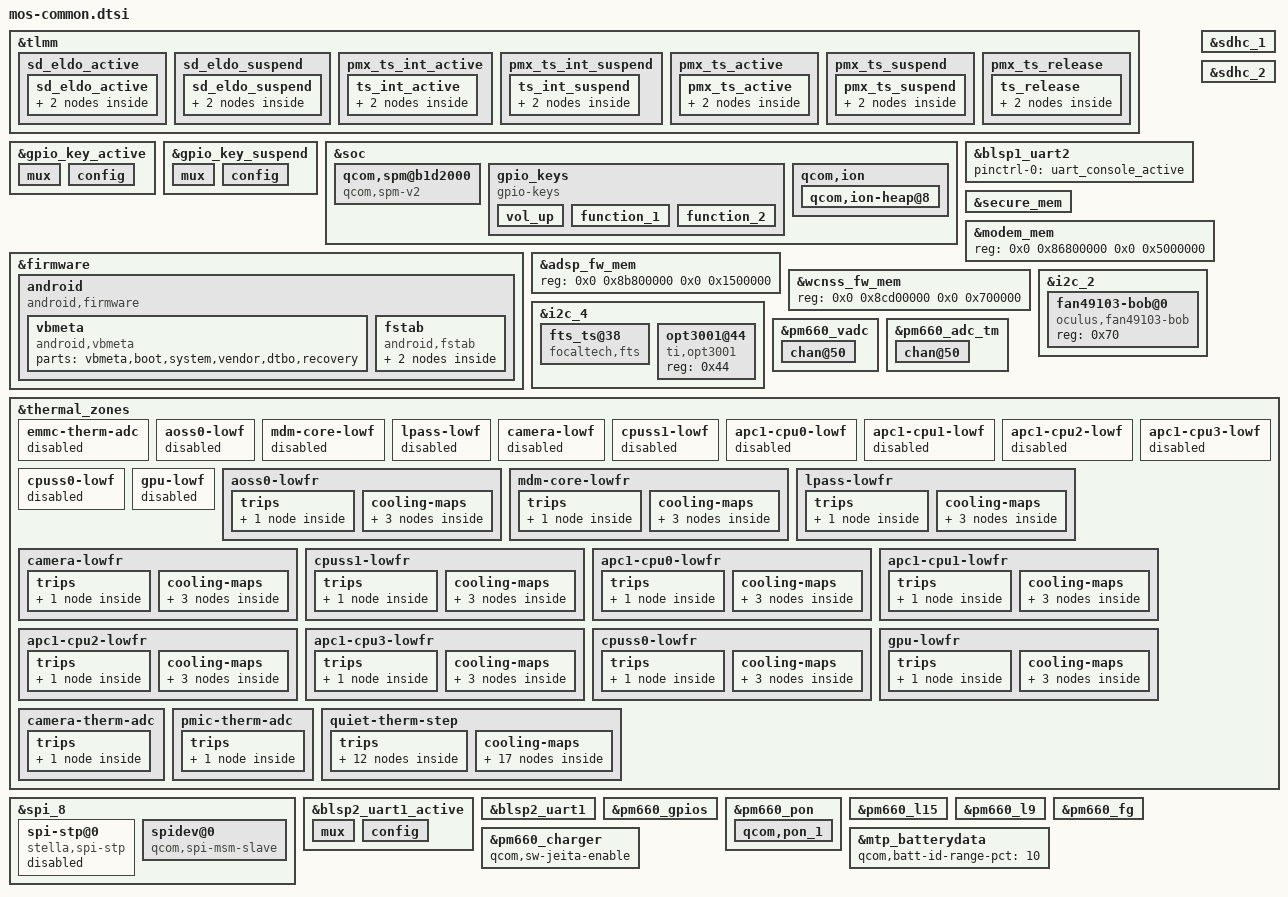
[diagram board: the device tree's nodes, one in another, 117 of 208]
/*
 * Copyright (c) 2019, The Linux Foundation. All rights reserved.
 *
 * This program is free software; you can redistribute it and/or modify
 * it under the terms of the GNU General Public License version 2 and
 * only version 2 as published by the Free Software Foundation.
 *
 * This program is distributed in the hope that it will be useful,
 * but WITHOUT ANY WARRANTY; without even the implied warranty of
 * MERCHANTABILITY or FITNESS FOR A PARTICULAR PURPOSE.  See the
 * GNU General Public License for more details.
 */

#include "mos-panels.dtsi"
#include "stella-camera.dtsi"
#include "stella-audio.dtsi"
#include "stella-rt600.dtsi"
#include <dt-bindings/interrupt-controller/irq.h>
#include <dt-bindings/thermal/thermal.h>

&tlmm {
	sd_eldo_active {
		sd_eldo_active: sd_eldo_active {
			mux {
				pins = "gpio91";
				function = "gpio";
			};

			config {
				pins = "gpio91";
				drive-strength = <2>;
				bias-pull-up;
			};
		};
	};

	sd_eldo_suspend {
		sd_eldo_suspend: sd_eldo_suspend {
			mux {
				pins = "gpio91";
				function = "gpio";
			};

			config {
				pins = "gpio91";
				drive-strength = <2>;
				bias-disable;
			};
		};
	};
};

&gpio_key_active {
	mux {
		pins = "gpio127", "gpio128", "gpio35", "gpio126";
		function = "gpio";
	};

	config {
		pins = "gpio127", "gpio128", "gpio35", "gpio126";
		drive-strength = <2>;
		bias-pull-up;
	};
};

&gpio_key_suspend {
	mux {
		pins = "gpio127", "gpio128", "gpio35", "gpio126";
		function = "gpio";
	};

	config {
		pins = "gpio127", "gpio128", "gpio35", "gpio126";
		drive-strength = <2>;
		bias-pull-up;
	};
};

&soc {
	/delete-node/ qcom,spm@b1d2000;
	qcom,spm@b1d2000 {
		compatible = "qcom,spm-v2";
		#address-cells = <1>;
		#size-cells = <1>;
		reg = <0xb1d2000 0x1000>;
		qcom,name = "system-cci";
		qcom,saw2-ver-reg = <0xfd0>;
		qcom,saw2-cfg = <0x14>;
		qcom,saw2-spm-dly= <0x3C102800>;
		qcom,saw2-spm-ctl = <0xe>;
		qcom,cpu-vctl-list = <&CPU0 &CPU1 &CPU2 &CPU3>;
		qcom,vctl-timeout-us = <500>;
		qcom,vctl-port = <0x0>;
		qcom,vctl-port-ub = <0x1>;
		qcom,pfm-port = <0x2>;
	};

	gpio_keys: gpio_keys {
		compatible = "gpio-keys";
		label = "gpio-keys";
		pinctrl-names = "default";
		pinctrl-0 = <&gpio_key_active>;
		pinctrl-1 = <&gpio_key_suspend>;

		vol_up: vol_up {
			label = "volume_up";
			gpios = <&tlmm 35 0x1>;
			linux,input-type = <1>;
			linux,code = <115>;
			debounce-interval = <15>;
			linux,can-disable;
			gpio-key,wakeup;
		};

		function_1: function_1 {
			label = "function_1";
			gpios = <&tlmm 127 0x1>;
			linux,input-type = <1>;
			linux,code = <116>;
			debounce-interval = <15>;
			linux,can-disable;
			gpio-key,wakeup;
		};

		function_2: function_2 {
			label = "function_2";
			gpios = <&tlmm 126 0x1>;
			linux,input-type = <1>;
			linux,code = <117>;
			debounce-interval = <15>;
			linux,can-disable;
			gpio-key,wakeup;
		};
	};
};

&blsp1_uart2 {
	status = "ok";
	pinctrl-names = "default";
	pinctrl-0 = <&uart_console_active>;
};

&sdhc_1 {
	/* device core power supply */
	vdd-supply = <&L19A>;
	qcom,vdd-voltage-level = <2900000 3200000>;
	qcom,vdd-current-level = <200 570000>;

	/* device communication power supply */
	vdd-io-supply = <&L13A>;
	qcom,vdd-io-always-on;
	qcom,vdd-io-lpm-sup;
	qcom,vdd-io-voltage-level = <1800000 1800000>;
	qcom,vdd-io-current-level = <0 60000>;

	pinctrl-names = "active", "sleep";
	pinctrl-0 = <&sdc1_clk_on &sdc1_cmd_on &sdc1_data_on &sdc1_rclk_on>;
	pinctrl-1 = <&sdc1_clk_off &sdc1_cmd_off &sdc1_data_off &sdc1_rclk_off>;

	qcom,clk-rates = <400000 20000000 25000000 50000000 100000000 192000000
								384000000>;
	qcom,nonremovable;
	qcom,bus-speed-mode = "HS400_1p8v", "HS200_1p8v", "DDR_1p8v";

	status = "ok";
};

&sdhc_2 {
	/* device core power supply for sd card*/
	vdd-supply = <&vreg_sd_vdd>;
	qcom,vdd-voltage-level = <2950000 2950000>;
	qcom,vdd-current-level = <15000 800000>;

	/* device communication power supply for msm_io*/
	vdd-io-supply = <&vreg_sd_pad>;
	qcom,vdd-io-voltage-level = <1800000 2950000>;
	qcom,vdd-io-current-level = <200 22000>;

	pinctrl-names = "active", "sleep";
	pinctrl-0 = <&sdc2_clk_on &sdc2_cmd_on &sdc2_data_on &sdc2_cd_on
							&sd_eldo_active>;
	pinctrl-1 = <&sdc2_clk_off &sdc2_cmd_off &sdc2_data_off &sdc2_cd_off
							&sd_eldo_suspend>;

	qcom,clk-rates = <400000 20000000 25000000 50000000 100000000
								200000000>;

	qcom,bus-speed-mode = "SDR12", "SDR25", "SDR50", "DDR50", "SDR104";

	status = "ok";
};

&firmware {
	android {
		compatible = "android,firmware";
		vbmeta {
			compatible = "android,vbmeta";
			parts = "vbmeta,boot,system,vendor,dtbo,recovery";
		};
		fstab {
			compatible = "android,fstab";
			vendor {
				compatible = "android,vendor";
				dev =
		"/dev/block/platform/soc/7824900.sdhci/by-name/vendor";
				type = "ext4";
				mnt_flags = "ro,barrier=1,discard";
				fsmgr_flags = "wait";
				status = "ok";
			};
			system {
				compatible = "android,system";
				dev =
		"/dev/block/platform/soc/7824900.sdhci/by-name/system";
				type = "ext4";
				mnt_flags = "ro,barrier=1,discard";
				fsmgr_flags = "wait";
				status = "ok";
			};
		};
	};
};

&soc {
	qcom,ion {
		qcom,ion-heap@8 { /* CP_MM HEAP */
			reg = <8>;
			memory-region = <&secure_mem>;
			qcom,ion-heap-type = "SECURE_DMA";
		};
	};
};

&secure_mem {
	alignment = <0 0x400000>;
	size = <0 0x800000>;
	status = "okay";
};

&modem_mem {
	reg = <0x0 0x86800000 0x0 0x5000000>;
};

&adsp_fw_mem {
	reg = <0x0 0x8b800000 0x0 0x1500000>;
};

&wcnss_fw_mem {
	reg = <0x0 0x8cd00000 0x0 0x700000>;
};

&i2c_2 {
	status = "ok";

	fan49103-bob@0 {
		compatible = "oculus,fan49103-bob";
		/*
		 * NOTE: datasheet shows 0xE0 as address, but need to right shift
		 *       by one to satisfy 7-bit requirement
		 */
		reg = <0x70>;
	};
};

&i2c_4 {
	status = "ok";

	fts_ts@38 {
		compatible = "focaltech,fts";
		reg = <0x38>;
		interrupt-parent = <&tlmm>;
		interrupts = <65 0x2>;
		focaltech,reset-gpio = <&tlmm 64 0x0>;
		focaltech,irq-gpio = <&tlmm 65 0x2008>;
		focaltech,max-touch-number = <5>;
		focaltech,display-coords = <0 0 390 390>;

		/* gpio used to select AP to control touchscreen */
		focaltech,ts-select-gpio = <&tlmm 61 0x0>;

		/* 0 (default, no-op) or 180.
		 * If 180, touch events are rotated to match display pixels. */
		focaltech,ts-orientation = <180>;

		/* pins used by touchscreen */
		pinctrl-names = "pmx_ts_active","pmx_ts_suspend",
			"pmx_ts_release";
		pinctrl-0 = <&ts_int_active>;
		pinctrl-1 = <&ts_int_suspend>;
		pinctrl-2 = <&ts_release>;
	};

	opt3001@44 {
		compatible = "ti,opt3001";
		reg = <0x44>;
	};

};

&tlmm {
	pmx_ts_int_active {
		ts_int_active: ts_int_active {
			mux {
				pins = "gpio65";
				function = "gpio";
			};

			config {
				pins = "gpio65";
				drive-strength = <8>;
				bias-pull-up;
			};
		};
	};

	pmx_ts_int_suspend {
		ts_int_suspend: ts_int_suspend {
			mux {
				pins = "gpio65";
				function = "gpio";
			};

			config {
				pins = "gpio65";
				drive-strength = <2>;
				bias-pull-down;
			};
		};
	};

	pmx_ts_active {
		pmx_ts_active: pmx_ts_active {
			mux {
				pins = "gpio64", "gpio61";
				function = "gpio";
			};

			config {
				pins = "gpio64", "gpio61";
				drive-strength = <8>;
				bias-pull-up;
			};
		};
	};

	pmx_ts_suspend {
		pmx_ts_suspend: pmx_ts_suspend {
			mux {
				pins = "gpio64", "gpio61";
				function = "gpio";
			};

			config {
				pins = "gpio64", "gpio61";
				drive-strength = <2>;
				bias-pull-down;
			};
		};
	};

	pmx_ts_release {
		ts_release: ts_release {
			mux {
				pins = "gpio65", "gpio64", "gpio61";
				function = "gpio";
			};

			config {
				pins = "gpio65", "gpio64", "gpio61";
				drive-strength = <2>;
				bias-pull-down;
			};
		};
	};

};

&pm660_vadc {
	chan@50 {
		label = "pmic_therm";
		reg = <0x50>;
		qcom,decimation = <2>;
		qcom,pre-div-channel-scaling = <0>;
		qcom,calibration-type = "ratiometric";
		qcom,scale-function = <2>;
		qcom,hw-settle-time = <2>;
		qcom,fast-avg-setup = <0>;
	};
};

&pm660_adc_tm {
	chan@50 {
		label = "pmic_therm";
		reg = <0x50>;
		qcom,pre-div-channel-scaling = <0>;
		qcom,calibration-type = "ratiometric";
		qcom,scale-function = <2>;
		qcom,hw-settle-time = <2>;
		qcom,btm-channel-number = <0x48>;
		qcom,thermal-node;
	};
};

&thermal_zones {

	emmc-therm-adc {
		status = "disabled";
	};

	aoss0-lowf {
		status = "disabled";
	};

	mdm-core-lowf {
		status = "disabled";
	};

	lpass-lowf {
		status = "disabled";
	};

	camera-lowf {
		status = "disabled";
	};

	cpuss1-lowf {
		status = "disabled";
	};

	apc1-cpu0-lowf {
		status = "disabled";
	};

	apc1-cpu1-lowf {
		status = "disabled";
	};

	apc1-cpu2-lowf {
		status = "disabled";
	};

	apc1-cpu3-lowf {
		status = "disabled";
	};

	cpuss0-lowf {
		status = "disabled";
	};

	gpu-lowf {
		status = "disabled";
	};

	aoss0-lowfr {
		polling-delay-passive = <0>;
		polling-delay = <0>;
		thermal-governor = "low_limits_floor";
		thermal-sensors = <&tsens0 0>;
		tracks-low;

		trips {
			aoss0_trip: aoss-trip {
				temperature = <5000>;
				hysteresis = <5000>;
				type = "passive";
			};
		};

		cooling-maps {
			cpu0_vdd_cdev {
				trip = <&aoss0_trip>;
				cooling-device = <&CPU0 (THERMAL_MAX_LIMIT-2)
						(THERMAL_MAX_LIMIT-2)>;
			};

			cx_vdd_cdev {
				trip = <&aoss0_trip>;
				cooling-device = <&pm660_cx_cdev 0 0>;
			};

			modem_vdd_cdev {
				trip = <&aoss0_trip>;
				cooling-device = <&modem_vdd 0 0>;
			};
		};
	};

	mdm-core-lowfr {
		polling-delay-passive = <0>;
		polling-delay = <0>;
		thermal-governor = "low_limits_floor";
		thermal-sensors = <&tsens0 1>;
		tracks-low;

		trips {
			mdm_core_trip: mdm-core-trip {
				temperature = <5000>;
				hysteresis = <5000>;
				type = "passive";
			};
		};

		cooling-maps {
			cpu0_vdd_cdev {
				trip = <&mdm_core_trip>;
				cooling-device = <&CPU0 (THERMAL_MAX_LIMIT-2)
						(THERMAL_MAX_LIMIT-2)>;
			};

			cx_vdd_cdev {
				trip = <&mdm_core_trip>;
				cooling-device = <&pm660_cx_cdev 0 0>;
			};

			modem_vdd_cdev {
				trip = <&mdm_core_trip>;
				cooling-device = <&modem_vdd 0 0>;
			};
		};
	};

	lpass-lowfr {
		polling-delay-passive = <0>;
		polling-delay = <0>;
		thermal-governor = "low_limits_floor";
		thermal-sensors = <&tsens0 2>;
		tracks-low;

		trips {
			qdsp_trip: qdsp-trip {
				temperature = <5000>;
				hysteresis = <5000>;
				type = "passive";
			};
		};

		cooling-maps {
			cpu0_vdd_cdev {
				trip = <&qdsp_trip>;
				cooling-device = <&CPU0 (THERMAL_MAX_LIMIT-2)
						(THERMAL_MAX_LIMIT-2)>;
			};

			cx_vdd_cdev {
				trip = <&qdsp_trip>;
				cooling-device = <&pm660_cx_cdev 0 0>;
			};

			modem_vdd_cdev {
				trip = <&qdsp_trip>;
				cooling-device = <&modem_vdd 0 0>;
			};
		};
	};

	camera-lowfr {
		polling-delay-passive = <0>;
		polling-delay = <0>;
		thermal-governor = "low_limits_floor";
		thermal-sensors = <&tsens0 3>;
		tracks-low;

		trips {
			camera_trip: camera-trip {
				temperature = <5000>;
				hysteresis = <5000>;
				type = "passive";
			};
		};

		cooling-maps {
			cpu0_vdd_cdev {
				trip = <&camera_trip>;
				cooling-device = <&CPU0 (THERMAL_MAX_LIMIT-2)
						(THERMAL_MAX_LIMIT-2)>;
			};

			cx_vdd_cdev {
				trip = <&camera_trip>;
				cooling-device = <&pm660_cx_cdev 0 0>;
			};

			modem_vdd_cdev {
				trip = <&camera_trip>;
				cooling-device = <&modem_vdd 0 0>;
			};
		};
	};

	cpuss1-lowfr {
		polling-delay-passive = <0>;
		polling-delay = <0>;
		thermal-governor = "low_limits_floor";
		thermal-sensors = <&tsens0 4>;
		tracks-low;

		trips {
			cpuss1_trip: cpuss1-trip {
				temperature = <5000>;
				hysteresis = <5000>;
				type = "passive";
			};
		};

		cooling-maps {
			cpu0_vdd_cdev {
				trip = <&cpuss1_trip>;
				cooling-device = <&CPU0 (THERMAL_MAX_LIMIT-2)
					(THERMAL_MAX_LIMIT-2)>;
			};

			cx_vdd_cdev {
				trip = <&cpuss1_trip>;
				cooling-device = <&pm660_cx_cdev 0 0>;
			};

			modem_vdd_cdev {
				trip = <&cpuss1_trip>;
				cooling-device = <&modem_vdd 0 0>;
			};
		};
	};

	apc1-cpu0-lowfr {
		polling-delay-passive = <0>;
		polling-delay = <0>;
		thermal-governor = "low_limits_floor";
		thermal-sensors = <&tsens0 5>;
		tracks-low;

		trips {
			cpu0_trip: apc1-cpu0-trip {
				temperature = <5000>;
				hysteresis = <5000>;
				type = "passive";
			};
		};

		cooling-maps {
			cpu0_vdd_cdev {
				trip = <&cpu0_trip>;
				cooling-device = <&CPU0 (THERMAL_MAX_LIMIT-2)
						(THERMAL_MAX_LIMIT-2)>;
			};

			cx_vdd_cdev {
				trip = <&cpu0_trip>;
				cooling-device = <&pm660_cx_cdev 0 0>;
			};

			modem_vdd_cdev {
				trip = <&cpu0_trip>;
				cooling-device = <&modem_vdd 0 0>;
			};
		};
	};

	apc1-cpu1-lowfr {
		polling-delay-passive = <0>;
		polling-delay = <0>;
		thermal-governor = "low_limits_floor";
		thermal-sensors = <&tsens0 6>;
		tracks-low;

		trips {
			cpu1_trip: apc1-cpu1-trip {
				temperature = <5000>;
				hysteresis = <5000>;
				type = "passive";
			};
		};

		cooling-maps {
			cpu0_vdd_cdev {
				trip = <&cpu1_trip>;
				cooling-device = <&CPU0 (THERMAL_MAX_LIMIT-2)
						(THERMAL_MAX_LIMIT-2)>;
			};

			cx_vdd_cdev {
				trip = <&cpu1_trip>;
				cooling-device = <&pm660_cx_cdev 0 0>;
			};

			modem_vdd_cdev {
				trip = <&cpu1_trip>;
				cooling-device = <&modem_vdd 0 0>;
			};
		};
	};

	apc1-cpu2-lowfr {
		polling-delay-passive = <0>;
		polling-delay = <0>;
		thermal-governor = "low_limits_floor";
		thermal-sensors = <&tsens0 7>;
		tracks-low;

		trips {
			cpu2_trip: apc1-cpu2-trip {
				temperature = <5000>;
				hysteresis = <5000>;
				type = "passive";
			};
		};

		cooling-maps {
			cpu0_vdd_cdev {
				trip = <&cpu2_trip>;
				cooling-device = <&CPU0 (THERMAL_MAX_LIMIT-2)
						(THERMAL_MAX_LIMIT-2)>;
			};

			cx_vdd_cdev {
				trip = <&cpu2_trip>;
				cooling-device = <&pm660_cx_cdev 0 0>;
			};

			modem_vdd_cdev {
				trip = <&cpu2_trip>;
				cooling-device = <&modem_vdd 0 0>;
			};
		};
	};

	apc1-cpu3-lowfr {
		polling-delay-passive = <0>;
		polling-delay = <0>;
		thermal-governor = "low_limits_floor";
		thermal-sensors = <&tsens0 8>;
		tracks-low;

		trips {
			cpu3_trip: apc1-cpu3-trip {
				temperature = <5000>;
				hysteresis = <5000>;
				type = "passive";
			};
		};

		cooling-maps {
			cpu0_vdd_cdev {
				trip = <&cpu3_trip>;
				cooling-device = <&CPU0 (THERMAL_MAX_LIMIT-2)
						(THERMAL_MAX_LIMIT-2)>;
			};

			cx_vdd_cdev {
				trip = <&cpu3_trip>;
				cooling-device = <&pm660_cx_cdev 0 0>;
			};

			modem_vdd_cdev {
				trip = <&cpu3_trip>;
				cooling-device = <&modem_vdd 0 0>;
			};
		};
	};

	cpuss0-lowfr {
		polling-delay-passive = <0>;
		polling-delay = <0>;
		thermal-governor = "low_limits_floor";
		thermal-sensors = <&tsens0 9>;
		tracks-low;

		trips {
			cpuss0_lowf_trip: cpuss0-lowf-trip {
				temperature = <5000>;
				hysteresis = <5000>;
				type = "passive";
			};
		};

		cooling-maps {
			cpu0_vdd_cdev {
				trip = <&cpuss0_lowf_trip>;
				cooling-device = <&CPU0 (THERMAL_MAX_LIMIT-2)
						(THERMAL_MAX_LIMIT-2)>;
			};

			cx_vdd_cdev {
				trip = <&cpuss0_lowf_trip>;
				cooling-device = <&pm660_cx_cdev 0 0>;
			};

			modem_vdd_cdev {
				trip = <&cpuss0_lowf_trip>;
				cooling-device = <&modem_vdd 0 0>;
			};
		};
	};

	gpu-lowfr {
		polling-delay-passive = <0>;
		polling-delay = <0>;
		thermal-governor = "low_limits_floor";
		thermal-sensors = <&tsens0 10>;
		tracks-low;

		trips {
			gpu_lowf_trip: gpu-lowf-trip {
				temperature = <5000>;
				hysteresis = <5000>;
				type = "passive";
			};
		};

		cooling-maps {
			cpu0_vdd_cdev {
				trip = <&gpu_lowf_trip>;
				cooling-device = <&CPU0 (THERMAL_MAX_LIMIT-2)
						(THERMAL_MAX_LIMIT-2)>;
			};

			cx_vdd_cdev {
				trip = <&gpu_lowf_trip>;
				cooling-device = <&pm660_cx_cdev 0 0>;
			};

			modem_vdd_cdev {
				trip = <&gpu_lowf_trip>;
				cooling-device = <&modem_vdd 0 0>;
			};
		};
	};

	camera-therm-adc {
		polling-delay-passive = <0>;
		polling-delay = <0>;
		thermal-sensors = <&pm660_adc_tm 0x4e>;
		wake-capable-sensor;
		thermal-governor = "user_space";

		trips {
			active-config0 {
				temperature = <65000>;
				hysteresis = <1000>;
				type = "passive";
			};
		};
	};

	pmic-therm-adc {
		polling-delay-passive = <0>;
		polling-delay = <0>;
		thermal-sensors = <&pm660_adc_tm 0x50>;
		wake-capable-sensor;
		thermal-governor = "user_space";

		trips {
			active-config0 {
				temperature = <65000>;
				hysteresis = <1000>;
				type = "passive";
			};
		};
	};

	quiet-therm-step {
		polling-delay-passive = <1000>;
		polling-delay = <0>;
		thermal-sensors = <&pm660_adc_tm 0x51>;
		thermal-governor = "step_wise";

		trips {
			quiet_batt_439_trip1: quiet-batt-trip1 {
				temperature = <38000>;
				hysteresis = <2000>;
				type = "passive";
			};

			quiet_batt_439_trip2: quiet-batt-trip2 {
				temperature = <40000>;
				hysteresis = <2000>;
				type = "passive";
			};

			quiet_batt_439_trip3: quiet-batt-trip3 {
				temperature = <42000>;
				hysteresis = <2000>;
				type = "passive";
			};

			quiet_batt_439_trip4: quiet-batt-trip4 {
				temperature = <44000>;
				hysteresis = <2000>;
				type = "passive";
			};

			quiet_modem_439_trip1: quiet-modem-trip0 {
				temperature = <44000>;
				hysteresis = <4000>;
				type = "passive";
			};

			quiet_modem_439_trip2: quiet-modem-trip1 {
				temperature = <46000>;
				hysteresis = <4000>;
				type = "passive";
			};

			quiet_batt_439_trip5: quiet-batt-trip5 {
				temperature = <46000>;
				hysteresis = <2000>;
				type = "passive";
			};

			quiet_439_batt_trip6_mdm_trip3: quiet-bt-trp6-mdm-trp3 {
				temperature = <48000>;
				hysteresis = <2000>;
				type = "passive";
			};

			quiet_cpus_439_trip: quiet-cpus-trip {
				temperature = <48000>;
				hysteresis = <0>;
				type = "passive";
			};

			quiet_gpu_439_trip: quiet-gpu-trip {
				temperature = <50000>;
				hysteresis = <0>;
				type = "passive";
			};

			quiet_batt_439_trip7: quiet-batt-trip7 {
				temperature = <50000>;
				hysteresis = <2000>;
				type = "passive";
			};

			quiet_modem_439_trip4: quiet-modem-trip3 {
				temperature = <55000>;
				hysteresis = <5000>;
				type = "passive";
			};
		};

		cooling-maps {
			skin_cpu0 {
				trip = <&quiet_cpus_439_trip>;
				/* throttle from fmax to 1497600KHz */
				cooling-device = <&CPU0 THERMAL_NO_LIMIT
						(THERMAL_MAX_LIMIT-3)>;
			};

			skin_cpu1 {
				trip = <&quiet_cpus_439_trip>;
				cooling-device = <&CPU1 THERMAL_NO_LIMIT
						(THERMAL_MAX_LIMIT-3)>;
			};

			skin_cpu2 {
				trip = <&quiet_cpus_439_trip>;
				cooling-device = <&CPU2 THERMAL_NO_LIMIT
						(THERMAL_MAX_LIMIT-3)>;
			};

			skin_cpu3 {
				trip = <&quiet_cpus_439_trip>;
				cooling-device = <&CPU3 THERMAL_NO_LIMIT
						(THERMAL_MAX_LIMIT-3)>;
			};

			skin_gpu {
				trip = <&quiet_gpu_439_trip>;
				/* throttle from fmax to 510000000Hz */
				cooling-device = <&msm_gpu THERMAL_NO_LIMIT
						(THERMAL_MAX_LIMIT-2)>;
			};

			modem_proc_lvl1 {
				trip = <&quiet_modem_439_trip1>;
				cooling-device = <&modem_proc 1 1>;
			};

			modem_proc_lvl2 {
				trip = <&quiet_modem_439_trip4>;
				cooling-device = <&modem_proc 3 3>;
			};

			modem_lvl1 {
				trip = <&quiet_modem_439_trip2>;
				cooling-device = <&modem_pa 1 1>;
			};

			modem_lvl2 {
				trip = <&quiet_439_batt_trip6_mdm_trip3>;
				cooling-device = <&modem_pa 2 2>;
			};

			modem_lvl3 {
				trip = <&quiet_modem_439_trip4>;
				cooling-device = <&modem_pa 3 3>;
			};

			battery_lvl1 {
				trip = <&quiet_batt_439_trip1>;
				cooling-device = <&pm660_charger 1 1>;
			};

			battery_lvl2 {
				trip = <&quiet_batt_439_trip2>;
				cooling-device = <&pm660_charger 2 2>;
			};

			battery_lvl3 {
				trip = <&quiet_batt_439_trip3>;
				cooling-device = <&pm660_charger 3 3>;
			};

			battery_lvl4 {
				trip = <&quiet_batt_439_trip4>;
				cooling-device = <&pm660_charger 4 4>;
			};

			battery_lvl5 {
				trip = <&quiet_batt_439_trip5>;
				cooling-device = <&pm660_charger 5 5>;
			};

			battery_lvl6 {
				trip = <&quiet_439_batt_trip6_mdm_trip3>;
				cooling-device = <&pm660_charger 6 6>;
			};

			battery_lvl7 {
				trip = <&quiet_batt_439_trip7>;
				cooling-device = <&pm660_charger 7 7>;
			};
		};
	};
};

&spi_8 {
	status = "ok";
	spi-stp@0 {
		status = "disabled";
		compatible= "stella,spi-stp";
		reg = <0>;
		spi-max-frequency = <20000000>;
		mcu-has-data  = <&tlmm 73 0>;
		mcu-ready  = <&tlmm 72 0>;
	};

	spidev@0 {
		status = "ok";
		compatible = "qcom,spi-msm-slave";
		reg = <0>;
		spi-max-frequency = <20000000>;
	};
};

&blsp2_uart1_active {
	mux {
		pins = "gpio16", "gpio17", "gpio18", "gpio19";
		function = "blsp_uart5";
	};

	config {
		pins = "gpio16", "gpio17", "gpio18", "gpio19";
		drive-strength = <2>;
		bias-disable;
	};
};

&blsp2_uart1 {
	status = "ok";
	/* disable RX wake interrupts */
	interrupt-names = "core_irq", "bam_irq";
	interrupts = <0 1>;
	interrupt-map = <0 &intc 0 306 0
			1 &intc 0 239 0>;
};

/* PMIC_USB_SWITC_EN_N, VREG_BOB_EN, AP_TO_RT600_RST_N */
&pm660_gpios {
	interrupts = <0x0 0xc0 0 IRQ_TYPE_NONE>,
			<0x0 0xc2 0 IRQ_TYPE_NONE>,
			<0x0 0xc7 0 IRQ_TYPE_NONE>;
	interrupt-names = "pm660_gpio1", "pm660_gpio3", "pm660_gpio8";
	qcom,gpios-disallowed = <2 4 5 6 7 9 10 11 12 13>;
};

&pm660_pon {
	/* Reset after pressing power for ~9 seconds */
	qcom,pon_1 {
		qcom,support-reset = <1>;
		qcom,s1-timer = <6720>;
		qcom,s2-timer = <2000>;
		qcom,s2-type = <8>;
	};
};

&pm660_l15 {
	regulator-min-microvolt = <2200000>;
	regulator-max-microvolt = <3400000>;
	qcom,init-voltage = <2200000>;
	regulator-always-on;
	regulator-boot-on;
};

&pm660_l9 {
	qcom,init-voltage = <1800000>;
	regulator-always-on;
	regulator-boot-on;
};

&pm660_fg {
	qcom,fg-cutoff-voltage = <3000>;
	qcom,fg-jeita-hyst-temp = <1>;
	qcom,fg-recharge-soc-thr = <95>;
	qcom,linearize-soc;
	qcom,fg-chg-term-current = <8>;
};

&pm660_charger {
	qcom,sw-jeita-enable;
};

&mtp_batterydata {
	qcom,batt-id-range-pct = <10>;
	#include "fg-gen3-batterydata-pwm3100-167mah.dtsi"
};
